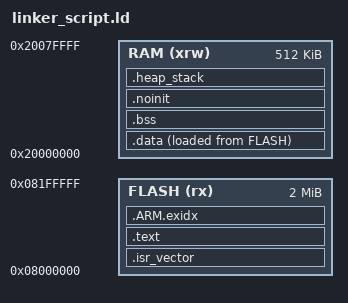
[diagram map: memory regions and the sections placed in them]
ENTRY(Reset_Handler)

_Min_Heap_Size = 0x0;
_Min_Stack_Size = 0x800;

MEMORY
{
    FLASH (rx)  : ORIGIN = 0x08000000, LENGTH = 2048K
    RAM   (xrw) : ORIGIN = 0x20000000, LENGTH = 512K
}

_estack = ORIGIN(RAM) + LENGTH(RAM);

SECTIONS
{
    .isr_vector :
    {
        . = ALIGN(4);
        KEEP(*(.isr_vector))
        . = ALIGN(4);
    } > FLASH

    .text :
    {
        . = ALIGN(4);
        *(.text*)
        *(.rodata*)
        *(.glue_7)
        *(.glue_7t)
        . = ALIGN(4);
        _etext = .;
    } > FLASH

    .ARM.exidx :
    {
        . = ALIGN(4);
        *(.ARM.exidx*)
        . = ALIGN(4);
    } > FLASH

    _sidata = LOADADDR(.data);

    .data :
    {
        . = ALIGN(4);
        _sdata = .;
        *(.data*)
        . = ALIGN(4);
        _edata = .;
    } > RAM AT > FLASH

    .bss (NOLOAD) :
    {
        . = ALIGN(4);
        _sbss = .;
        *(.bss*)
        *(COMMON)
        . = ALIGN(4);
        _ebss = .;
    } > RAM

    .noinit (NOLOAD) :
    {
        . = ALIGN(4);
        *(.noinit*)
        . = ALIGN(4);
    } > RAM

    .heap_stack (NOLOAD) :
    {
        . = ALIGN(8);
        . = . + _Min_Heap_Size;
        . = . + _Min_Stack_Size;
        . = ALIGN(8);
    } > RAM
}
